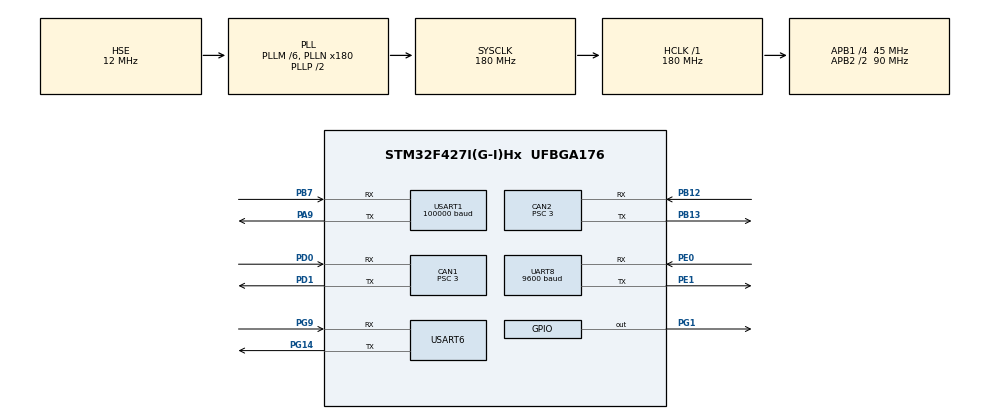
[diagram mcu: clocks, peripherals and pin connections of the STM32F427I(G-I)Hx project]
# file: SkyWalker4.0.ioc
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CAN1.BS1=CAN_BS1_10TQ
CAN1.BS2=CAN_BS2_4TQ
CAN1.CalculateBaudRate=1000000
CAN1.CalculateTimeBit=999
CAN1.CalculateTimeQuantum=66.66666666666666
CAN1.Prescaler=3
CAN2.BS1=CAN_BS1_10TQ
CAN2.BS2=CAN_BS2_4TQ
CAN2.CalculateBaudRate=1000000
CAN2.CalculateTimeBit=1000
CAN2.CalculateTimeQuantum=66.66666666666666
CAN2.Prescaler=3
Dma.Request0=USART1_RX
Dma.Request1=UART8_RX
Dma.Request2=USART6_RX
Dma.UART8_RX.1.Direction=DMA_PERIPH_TO_MEMORY
Dma.UART8_RX.1.FIFOMode=DMA_FIFOMODE_DISABLE
Dma.UART8_RX.1.Instance=DMA1_Stream6
Dma.UART8_RX.1.MemDataAlignment=DMA_MDATAALIGN_BYTE
Dma.UART8_RX.1.MemInc=DMA_MINC_ENABLE
Dma.UART8_RX.1.Mode=DMA_NORMAL
Dma.UART8_RX.1.PeriphDataAlignment=DMA_PDATAALIGN_BYTE
Dma.UART8_RX.1.PeriphInc=DMA_PINC_DISABLE
Dma.UART8_RX.1.Priority=DMA_PRIORITY_HIGH
Dma.USART1_RX.0.Direction=DMA_PERIPH_TO_MEMORY
Dma.USART1_RX.0.FIFOMode=DMA_FIFOMODE_DISABLE
Dma.USART1_RX.0.Instance=DMA2_Stream2
Dma.USART1_RX.0.MemDataAlignment=DMA_MDATAALIGN_BYTE
Dma.USART1_RX.0.MemInc=DMA_MINC_ENABLE
Dma.USART1_RX.0.Mode=DMA_NORMAL
Dma.USART1_RX.0.PeriphDataAlignment=DMA_PDATAALIGN_BYTE
Dma.USART1_RX.0.PeriphInc=DMA_PINC_DISABLE
Dma.USART1_RX.0.Priority=DMA_PRIORITY_HIGH
Dma.USART6_RX.2.Direction=DMA_PERIPH_TO_MEMORY
Dma.USART6_RX.2.FIFOMode=DMA_FIFOMODE_DISABLE
Dma.USART6_RX.2.Instance=DMA2_Stream1
Dma.USART6_RX.2.MemDataAlignment=DMA_MDATAALIGN_BYTE
Dma.USART6_RX.2.MemInc=DMA_MINC_ENABLE
Dma.USART6_RX.2.Mode=DMA_NORMAL
Dma.USART6_RX.2.PeriphDataAlignment=DMA_PDATAALIGN_BYTE
Dma.USART6_RX.2.PeriphInc=DMA_PINC_DISABLE
Dma.USART6_RX.2.Priority=DMA_PRIORITY_HIGH
Mcu.Family=STM32F4
Mcu.Name=STM32F427I(G-I)Hx
Mcu.Package=UFBGA176
NVIC.CAN1_RX0_IRQn=true\:0\:0\:false\:false\:true\:true\:true\:true
NVIC.CAN1_RX1_IRQn=true\:0\:0\:false\:false\:true\:true\:true\:true
NVIC.CAN1_SCE_IRQn=true\:0\:0\:false\:false\:true\:true\:true\:true
NVIC.CAN2_RX0_IRQn=true\:0\:0\:false\:false\:true\:true\:true\:true
NVIC.CAN2_RX1_IRQn=true\:0\:0\:false\:false\:true\:true\:true\:true
NVIC.CAN2_SCE_IRQn=true\:0\:0\:false\:false\:true\:true\:true\:true
NVIC.DMA1_Stream6_IRQn=true\:0\:0\:false\:false\:true\:false\:true\:true
NVIC.DMA2_Stream1_IRQn=true\:0\:0\:false\:false\:true\:false\:true\:true
NVIC.DMA2_Stream2_IRQn=true\:0\:0\:false\:false\:true\:false\:true\:true
NVIC.PriorityGroup=NVIC_PRIORITYGROUP_4
NVIC.UART8_IRQn=true\:0\:0\:false\:false\:true\:true\:true\:true
NVIC.USART1_IRQn=true\:0\:0\:false\:false\:true\:true\:true\:true
NVIC.USART6_IRQn=true\:0\:0\:false\:false\:true\:true\:true\:true
PA13.Mode=Serial_Wire
PA13.Signal=SYS_JTMS-SWDIO
PA14.Mode=Serial_Wire
PA14.Signal=SYS_JTCK-SWCLK
PA9.Mode=Asynchronous
PA9.Signal=USART1_TX
PB12.Mode=CAN_Activate
PB12.Signal=CAN2_RX
PB13.Mode=CAN_Activate
PB13.Signal=CAN2_TX
PB7.Mode=Asynchronous
PB7.Signal=USART1_RX
PC14/OSC32_IN.Mode=LSE-External-Oscillator
PC14/OSC32_IN.Signal=RCC_OSC32_IN
PC15/OSC32_OUT.Mode=LSE-External-Oscillator
PC15/OSC32_OUT.Signal=RCC_OSC32_OUT
PD0.Mode=CAN_Activate
PD0.Signal=CAN1_RX
PD1.Mode=CAN_Activate
PD1.Signal=CAN1_TX
PE0.Mode=Asynchronous
PE0.Signal=UART8_RX
PE1.Mode=Asynchronous
PE1.Signal=UART8_TX
PG1.Signal=GPIO_Output
PG14.Mode=Asynchronous
PG14.Signal=USART6_TX
PG9.Mode=Asynchronous
PG9.Signal=USART6_RX
PH0/OSC_IN.Mode=HSE-External-Oscillator
PH0/OSC_IN.Signal=RCC_OSC_IN
PH1/OSC_OUT.Mode=HSE-External-Oscillator
PH1/OSC_OUT.Signal=RCC_OSC_OUT
ProjectManager.HeapSize=0x200
ProjectManager.StackSize=0x400
ProjectManager.TargetToolchain=CMake
RCC.48MHZClocksFreq_Value=51428571.428571425
RCC.AHBFreq_Value=180000000
RCC.APB1CLKDivider=RCC_HCLK_DIV4
RCC.APB1Freq_Value=45000000
RCC.APB1TimFreq_Value=90000000
RCC.APB2CLKDivider=RCC_HCLK_DIV2
RCC.APB2Freq_Value=90000000
RCC.APB2TimFreq_Value=180000000
RCC.CortexFreq_Value=180000000
RCC.HCLKFreq_Value=180000000
RCC.HSE_VALUE=12000000
RCC.HSI_VALUE=16000000
RCC.PLLM=6
RCC.PLLN=180
RCC.PLLQ=7
RCC.PLLSourceVirtual=RCC_PLLSOURCE_HSE
RCC.SYSCLKFreq_VALUE=180000000
RCC.SYSCLKSource=RCC_SYSCLKSOURCE_PLLCLK
RCC.VCOOutputFreq_Value=360000000
UART8.BaudRate=9600
UART8.VirtualMode=Asynchronous
USART1.BaudRate=100000
USART1.Parity=PARITY_EVEN
USART1.StopBits=STOPBITS_2
USART1.VirtualMode=VM_ASYNC
USART1.WordLength=WORDLENGTH_9B
USART6.VirtualMode=VM_ASYNC
board=custom

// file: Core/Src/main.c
/* USER CODE BEGIN Header */
/**
  ******************************************************************************
  * @file           : main.c
  * @brief          : Main program body
  ******************************************************************************
  * @attention
  *
  * Copyright (c) 2026 STMicroelectronics.
  * All rights reserved.
  *
  * This software is licensed under terms that can be found in the LICENSE file
  * in the root directory of this software component.
  * If no LICENSE file comes with this software, it is provided AS-IS.
  *
  ******************************************************************************
  */
/* USER CODE END Header */
#include "main.h"
#include "can.h"
#include "dma.h"
#include "usart.h"
#include "gpio.h"

/* USER CODE BEGIN Includes */
#include "sbus.h"
#include "BottomControl.h"
#include "ArmControl.h"
/* USER CODE END Includes */

void SystemClock_Config(void);

/* USER CODE BEGIN 0 */

BottomControl Bottom;  // 创建底盘
// ArmControl Arm;  // 创建机械臂

/* USER CODE END 0 */

int main(void)
{

  /* USER CODE BEGIN 1 */
  BSPLogInit();  // rtt调试器初始化
  /* USER CODE END 1 */

  /* MCU Configuration--------------------------------------------------------*/

  /* Reset of all peripherals, Initializes the Flash interface and the Systick. */
  HAL_Init();

  /* Configure the system clock */
  SystemClock_Config();

  /* Initialize all configured peripherals */
  MX_GPIO_Init();
  MX_DMA_Init();
  MX_CAN1_Init();
  MX_CAN2_Init();
  MX_USART1_UART_Init();
  MX_UART8_Init();
  MX_USART6_UART_Init();
  /* USER CODE BEGIN 2 */

  SBUS_Init();
  //ArmInit(&Arm, &hcan1);
  BottomInit(&Bottom, &hcan1);

  uint32_t last = HAL_GetTick();
  /* USER CODE END 2 */

  /* Infinite loop */
  /* USER CODE BEGIN WHILE */
  while (1)
  {
    //PrintLog("hello\n");  // 发送日志
    // 发送波形 发送两个数据 可以在示波器上指定显示方式

    if (HAL_GetTick() - last >= 10)
    {
      last = HAL_GetTick();
      //摇杆输入 按照对应的通道对应控制方向
      SbusI6Mode(&Bottom, rc.channels[1], rc.channels[0], rc.channels[3]);
      BottomUpdate(&Bottom);

      BottomMotorSpeedlog(&Bottom, 2);

      //ArmUpdate(&Arm);
    }
    /* USER CODE END WHILE */

  }
}

void SystemClock_Config(void)
{
  RCC_OscInitTypeDef RCC_OscInitStruct = {0};
  RCC_ClkInitTypeDef RCC_ClkInitStruct = {0};

  /** Configure the main internal regulator output voltage
  */
  __HAL_RCC_PWR_CLK_ENABLE();
  __HAL_PWR_VOLTAGESCALING_CONFIG(PWR_REGULATOR_VOLTAGE_SCALE1);

  /** Initializes the RCC Oscillators according to the specified parameters
  * in the RCC_OscInitTypeDef structure.
  */
  RCC_OscInitStruct.OscillatorType = RCC_OSCILLATORTYPE_HSE;
  RCC_OscInitStruct.HSEState = RCC_HSE_ON;
  RCC_OscInitStruct.PLL.PLLState = RCC_PLL_ON;
  RCC_OscInitStruct.PLL.PLLSource = RCC_PLLSOURCE_HSE;
  RCC_OscInitStruct.PLL.PLLM = 6;
  RCC_OscInitStruct.PLL.PLLN = 180;
  RCC_OscInitStruct.PLL.PLLP = RCC_PLLP_DIV2;
  RCC_OscInitStruct.PLL.PLLQ = 7;
  if (HAL_RCC_OscConfig(&RCC_OscInitStruct) != HAL_OK)
  {
    Error_Handler();
  }

  /** Activate the Over-Drive mode
  */
  if (HAL_PWREx_EnableOverDrive() != HAL_OK)
  {
    Error_Handler();
  }

  /** Initializes the CPU, AHB and APB buses clocks
  */
  RCC_ClkInitStruct.ClockType = RCC_CLOCKTYPE_HCLK|RCC_CLOCKTYPE_SYSCLK
                              |RCC_CLOCKTYPE_PCLK1|RCC_CLOCKTYPE_PCLK2;
  RCC_ClkInitStruct.SYSCLKSource = RCC_SYSCLKSOURCE_PLLCLK;
  RCC_ClkInitStruct.AHBCLKDivider = RCC_SYSCLK_DIV1;
  RCC_ClkInitStruct.APB1CLKDivider = RCC_HCLK_DIV4;
  RCC_ClkInitStruct.APB2CLKDivider = RCC_HCLK_DIV2;

  if (HAL_RCC_ClockConfig(&RCC_ClkInitStruct, FLASH_LATENCY_5) != HAL_OK)
  {
    Error_Handler();
  }
}

void Error_Handler(void)
{
  __disable_irq();
  while (1)
  {
  }
}
